# netx90_app register map
File version: 1.0
CPU: CM4 r0p1, little endian, MPU, FPU, 4 interrupt priority bits, 78 interrupts
Registers are 32-bit, read-write, reset 0x0 unless marked. A register's access mark holds for its fields unless they carry their own. Offsets are from the block's base; [hi:lo] are bit positions; {n}, {i} and the like mark numbered series; 'fields as' and 'values as' point back to an identical list.

## pio_app
Base 0xFF801500
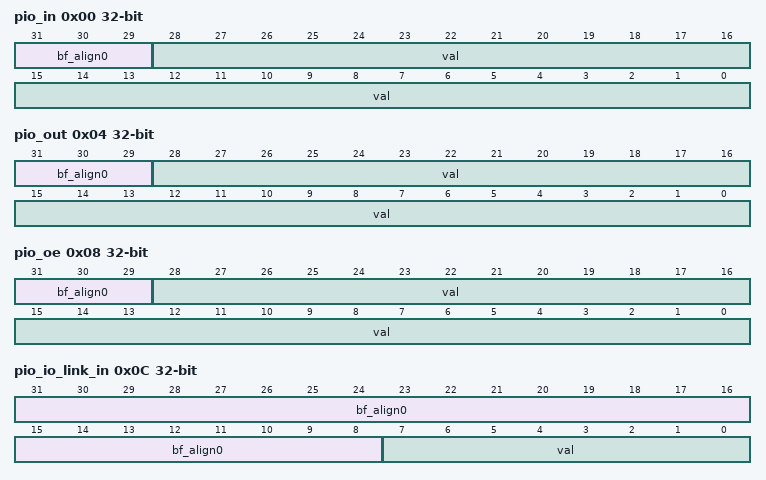
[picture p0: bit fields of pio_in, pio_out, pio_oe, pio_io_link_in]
0x00 pio_in ro (reset mask 0x1FFFFFFF) — PIO input line status register. Each PIO input status can also be read from dedicated PIOx input state register.
  [31:29] bf_align0 — bitField alignment value for aeabi compatibility
  [28:0] val — PIO input states (LSB: PIO0).
0x04 pio_out (reset mask 0x1FFFFFFF) — PIO output drive level line register. Each PIOs output drive level can also be programmed by dedicated PIOx output drive level register.
  [31:29] bf_align0 — bitField alignment value for aeabi compatibility
  [28:0] val — PIO output drive levels (LSB: PIO0).
0x08 pio_oe (reset mask 0x1FFFFFFF) — PIO output enable line register. Each PIOs output enable can also be programmed by dedicated PIOx output enable register.
  [31:29] bf_align0 — bitField alignment value for aeabi compatibility
  [28:0] val — PIO output enables (LSB: PIO0).
0x0C pio_io_link_in ro (reset mask 0xFF) — IO-Link input values. This register collects the inputs of 8 IO-Link ports for use in IO-Link IO-mode. In this mode the output and output-enable values are set by PIO pins independant on xPIC or IO-Link module. The relation of IO-Link-pin and PIO-pin can be seen in the global netX90 pinning sheet: io_link7_out->pio27, io_link7_oe->pio28 io_link6_out->pio24, io_link6_oe->pio25 io_link5_out->pio22, io_link5_oe->pio23 io_link4_out->pio19, io_link4_oe->pio21 io_link3_out->pio14, io_link3_oe->pio15 io_link2_out->pio11, io_link2_oe->pio13 io_link1_out/oe: configurable via multiplexmatrix on pio7:0 io_link0_out/oe: configurable via multiplexmatrix on pio7:0
  [31:8] bf_align0 — bitField alignment value for aeabi compatibility
  [7:0] val — IO-Link input
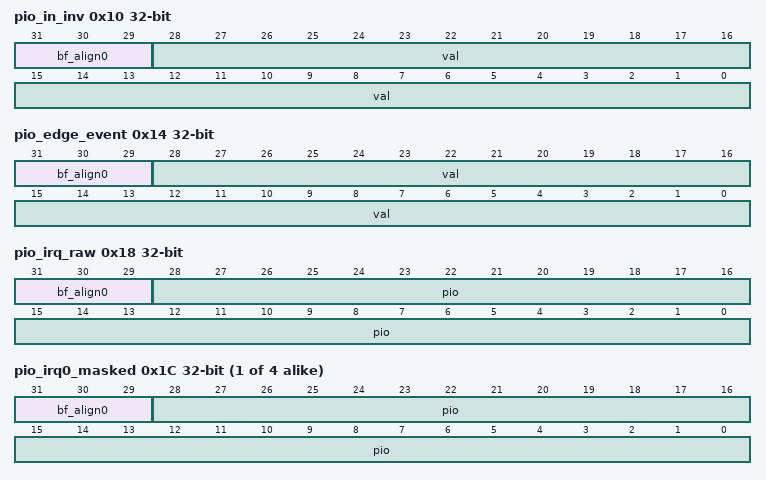
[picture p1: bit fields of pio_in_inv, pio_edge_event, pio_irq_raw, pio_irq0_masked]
0x10 pio_in_inv (reset mask 0x1FFFFFFF) — Invert input of PIO.
  [31:29] bf_align0 — bitField alignment value for aeabi compatibility
  [28:0] val — Invert PIO
0x14 pio_edge_event (reset mask 0x1FFFFFFF) — generate IRQ at edge of PIO, otherwise level.
  [31:29] bf_align0 — bitField alignment value for aeabi compatibility
  [28:0] val — Edge detect 0: generate IRQ if (inverted) PIO is high level 1: generate IRQ at rising edge of (inverted) PIO
0x18 pio_irq_raw (reset mask 0x1FFFFFFF) — Raw IRQ: Read access shows status of unmasked IRQs. IRQs are set automatically and reset by writing to this register: Write access with '1' resets the appropriate IRQ (if event irq, reset status irqs at their source). Write access with '0' does not influence this bit.
  [31:29] bf_align0 — bitField alignment value for aeabi compatibility
  [28:0] pio — event or active level at PIO input
{0x1C+0xC*i} pio_irq{i}_masked ro (reset mask 0x1FFFFFFF) (i=0..3) — Masked IRQ: Shows status of masked IRQs (as connected to ARM/xPIC).
  fields as pio_irq_raw
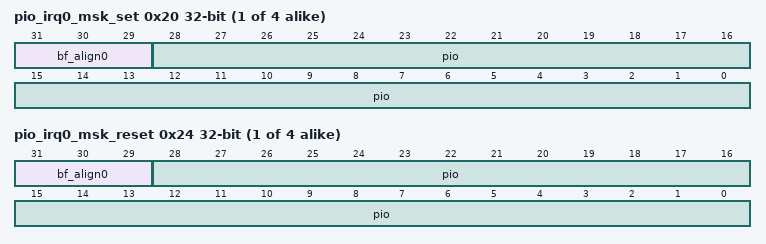
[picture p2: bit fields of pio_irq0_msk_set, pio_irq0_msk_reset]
{0x20+0xC*i} pio_irq{i}_msk_set (reset mask 0x1FFFFFFF) (i=0..3) — IRQ enable mask: The IRQ mask enables interrupt requests for corresponding interrupt sources. As its bits might be changed by different software tasks, the IRQ mask register is not writable directly, but by set and reset masks: Write access with '1' sets interrupt mask bit. Write access with '0' does not influence this bit. Read access shows actual interrupt mask. Attention: Before activating interrupt mask, delete old pending interrupts by writing the same value to adr_pio_irq_raw.
  fields as pio_irq_raw
{0x24+0xC*i} pio_irq{i}_msk_reset (reset mask 0x1FFFFFFF) (i=0..3) — IRQ disable mask: This is the corresponding reset mask to disable interrupt requests for corresponding interrupt sources: Write access with '1' resets interrupt mask bit. Write access with '0' does not influence this bit.
  fields as pio_irq_raw

## systime_lt_app
Base 0xFF801680
Same registers: systime_lt_xpic_app 0xFF9001C0
0x00 intlogic_lt_systime_com_ns ro — systime_com_ns last latched value
  [31:0] val
0x04 intlogic_lt_systime_com_s ro — systime_com_s last latched value
  [31:0] val
0x08 intlogic_lt_systime_com_uc_ns ro — systime_com_uc_ns last latched value
  [31:0] val
0x0C intlogic_lt_systime_com_uc_s ro — systime_com_uc_s last latched value
  [31:0] val
0x10 intlogic_lt_systime_app_ns ro — systime_app_ns last latched value
  [31:0] val
0x14 intlogic_lt_systime_app_s ro — systime_app_s last latched value
  [31:0] val
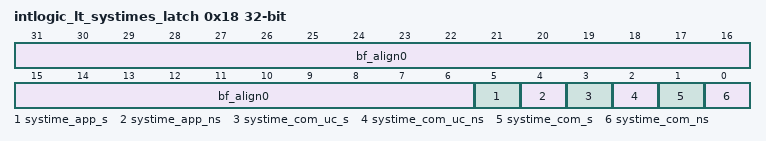
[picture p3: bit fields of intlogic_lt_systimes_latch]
0x18 intlogic_lt_systimes_latch wo (reset mask 0x3F) — latch systimes by writing 1'b1 to the assigned bit
  [31:6] bf_align0 — bitField alignment value for aeabi compatibility
  [5] systime_app_s — no field descpription
  [4] systime_app_ns — no field descpription
  [3] systime_com_uc_s — no field descpription
  [2] systime_com_uc_ns — no field descpription
  [1] systime_com_s — no field descpription
  [0] systime_com_ns — no field descpription
